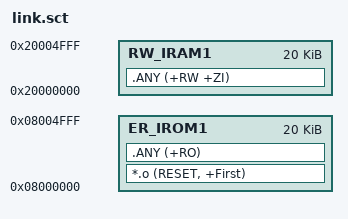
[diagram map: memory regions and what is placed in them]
; *************************************************************
; *** Bootloader Scatter File (ARMCC)
; *** Base: 0x08000000  Size: 6 KB (0x1800)
; *************************************************************

; Bootloader 20KB + 20KB RAM
LR_IROM1 0x08000000 0x00005000  {
  ER_IROM1 0x08000000 0x00005000  {
   *.o (RESET, +First)
   .ANY (+RO)
  }
  RW_IRAM1 0x20000000 0x00005000  {
   .ANY (+RW +ZI)
  }
}
